# io1986BE1T register map
Registers are 32-bit, access not given, no defined reset value unless marked. A register's access mark holds for its fields unless they carry their own. Addresses are absolute; registers are grouped by the start of their names; [hi:lo] are bit positions; {n}, {i} and the like mark numbered series; 'fields as' and 'values as' point back to an identical list.

## SSP2
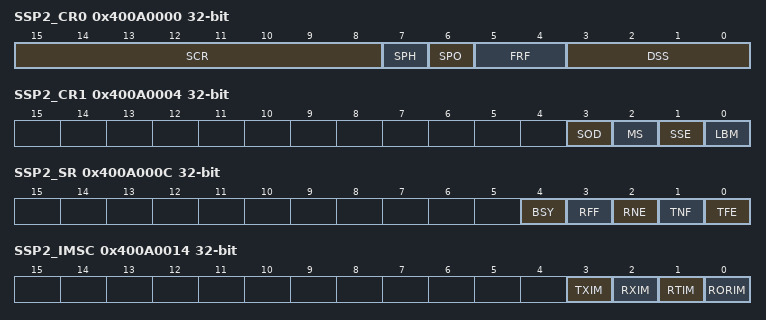
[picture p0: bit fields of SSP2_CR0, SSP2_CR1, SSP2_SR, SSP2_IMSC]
0x400A0000 SSP2_CR0
  [15:8] SCR, [7] SPH, [6] SPO, [5:4] FRF, [3:0] DSS
0x400A0004 SSP2_CR1
  [3] SOD, [2] MS, [1] SSE, [0] LBM
0x400A0008 SSP2_DR
  [15:0] DATA
0x400A000C SSP2_SR
  [4] BSY, [3] RFF, [2] RNE, [1] TNF, [0] TFE
0x400A0010 SSP2_CPSR
  [7:0] CPSDVSR
0x400A0014 SSP2_IMSC
  [3] TXIM, [2] RXIM, [1] RTIM, [0] RORIM
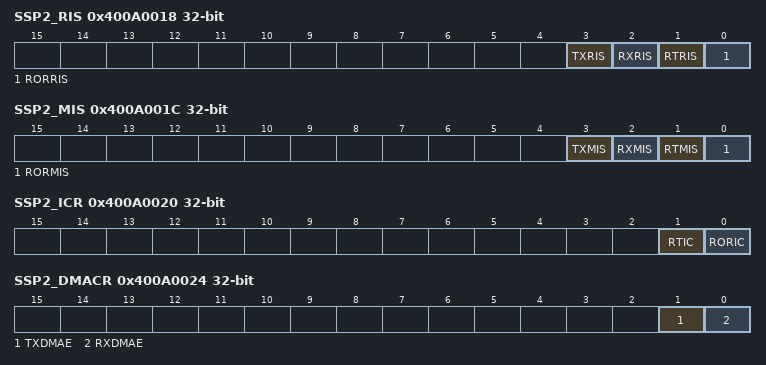
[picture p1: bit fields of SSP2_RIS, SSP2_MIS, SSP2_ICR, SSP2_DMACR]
0x400A0018 SSP2_RIS
  [3] TXRIS, [2] RXRIS, [1] RTRIS, [0] RORRIS
0x400A001C SSP2_MIS
  [3] TXMIS, [2] RXMIS, [1] RTMIS, [0] RORMIS
0x400A0020 SSP2_ICR
  [1] RTIC, [0] RORIC
0x400A0024 SSP2_DMACR
  [1] TXDMAE, [0] RXDMAE

## MIL
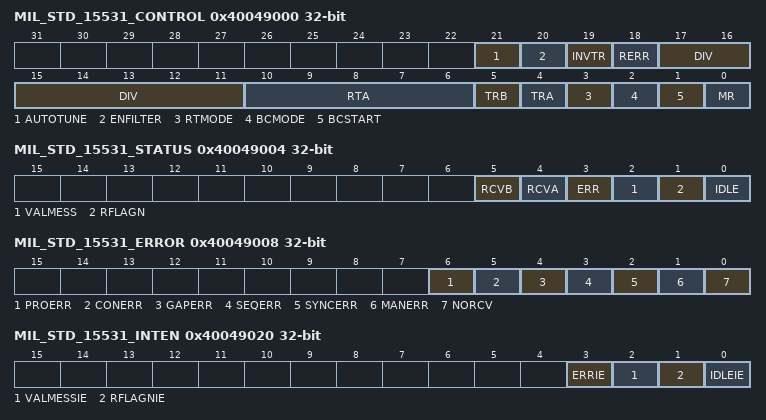
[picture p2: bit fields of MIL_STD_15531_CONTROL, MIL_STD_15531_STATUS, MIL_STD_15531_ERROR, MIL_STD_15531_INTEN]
0x40049000 MIL_STD_15531_CONTROL
  [21] AUTOTUNE, [20] ENFILTER, [19] INVTR, [18] RERR, [17:11] DIV, [10:6] RTA, [5] TRB, [4] TRA, [3] RTMODE, [2] BCMODE, [1] BCSTART, [0] MR
0x40049004 MIL_STD_15531_STATUS
  [5] RCVB, [4] RCVA, [3] ERR, [2] VALMESS, [1] RFLAGN, [0] IDLE
0x40049008 MIL_STD_15531_ERROR
  [6] PROERR, [5] CONERR, [4] GAPERR, [3] SEQERR, [2] SYNCERR, [1] MANERR, [0] NORCV
0x4004900C MIL_STD_15531_CommandWord1
0x40049010 MIL_STD_15531_CommandWord2
0x40049014 MIL_STD_15531_ModeData
0x40049018 MIL_STD_15531_StatusWord1
0x4004901C MIL_STD_15531_StatusWord2
0x40049020 MIL_STD_15531_INTEN
  [3] ERRIE, [2] VALMESSIE, [1] RFLAGNIE, [0] IDLEIE
0x40049024 MIL_STD_15531_MSG
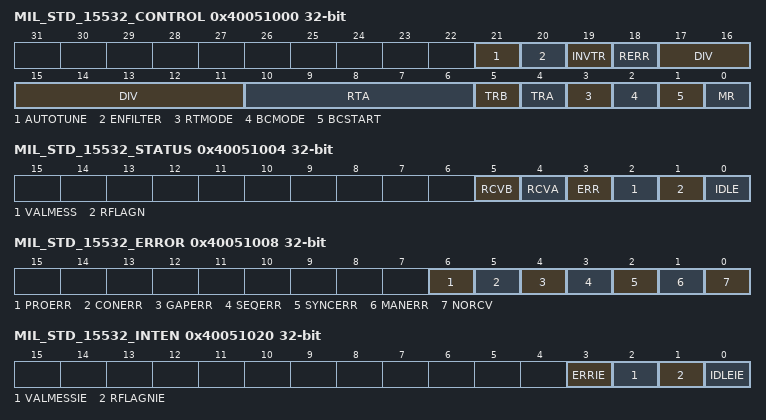
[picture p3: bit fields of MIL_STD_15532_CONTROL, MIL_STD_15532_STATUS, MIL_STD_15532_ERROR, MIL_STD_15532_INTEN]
0x40051000 MIL_STD_15532_CONTROL
  fields as MIL_STD_15531_CONTROL
0x40051004 MIL_STD_15532_STATUS
  [5] RCVB, [4] RCVA, [3] ERR, [2] VALMESS, [1] RFLAGN, [0] IDLE
0x40051008 MIL_STD_15532_ERROR
  fields as MIL_STD_15531_ERROR
0x4005100C MIL_STD_15532_CommandWord1
0x40051010 MIL_STD_15532_CommandWord2
0x40051014 MIL_STD_15532_ModeData
0x40051018 MIL_STD_15532_StatusWord1
0x4005101C MIL_STD_15532_StatusWord2
0x40051020 MIL_STD_15532_INTEN
  [3] ERRIE, [2] VALMESSIE, [1] RFLAGNIE, [0] IDLEIE
0x40051024 MIL_STD_15532_MSG

## ARINC429T
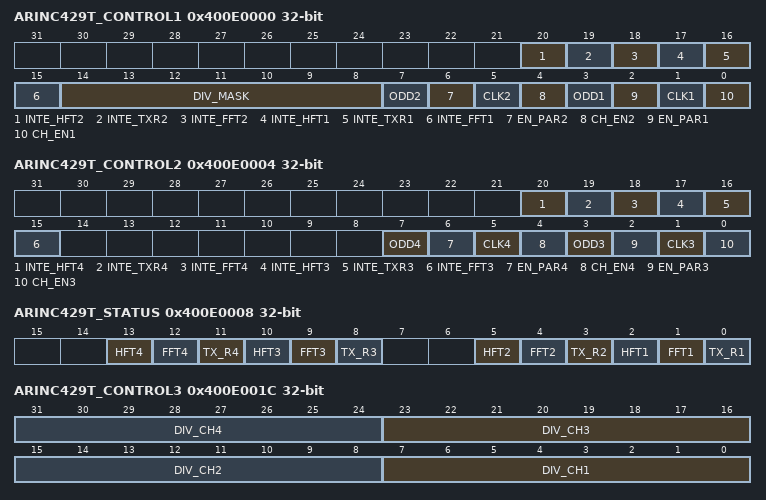
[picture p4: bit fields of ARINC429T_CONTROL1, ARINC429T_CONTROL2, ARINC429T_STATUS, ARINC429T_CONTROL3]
0x400E0000 ARINC429T_CONTROL1
  [20] INTE_HFT2, [19] INTE_TXR2, [18] INTE_FFT2, [17] INTE_HFT1, [16] INTE_TXR1, [15] INTE_FFT1, [14:8] DIV_MASK, [7] ODD2, [6] EN_PAR2, [5] CLK2, [4] CH_EN2, [3] ODD1, [2] EN_PAR1, [1] CLK1, [0] CH_EN1
0x400E0004 ARINC429T_CONTROL2
  [20] INTE_HFT4, [19] INTE_TXR4, [18] INTE_FFT4, [17] INTE_HFT3, [16] INTE_TXR3, [15] INTE_FFT3, [7] ODD4, [6] EN_PAR4, [5] CLK4, [4] CH_EN4, [3] ODD3, [2] EN_PAR3, [1] CLK3, [0] CH_EN3
0x400E0008 ARINC429T_STATUS
  [13] HFT4, [12] FFT4, [11] TX_R4, [10] HFT3, [9] FFT3, [8] TX_R3, [5] HFT2, [4] FFT2, [3] TX_R2, [2] HFT1, [1] FFT1, [0] TX_R1
{0x400E0008+4i} ARINC429T_DATA{i}_T (i=1..4)
0x400E001C ARINC429T_CONTROL3
  [8n-1:8n-8] DIV_CH{n} (n=1..4)

## ARINC429R
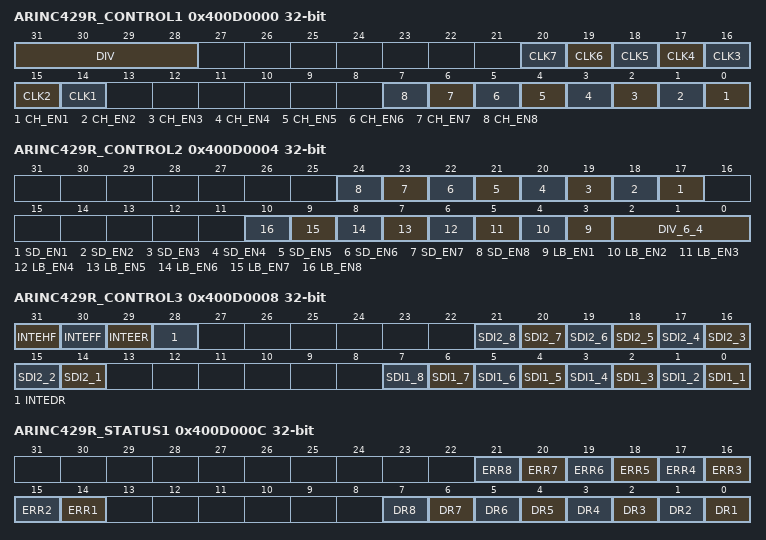
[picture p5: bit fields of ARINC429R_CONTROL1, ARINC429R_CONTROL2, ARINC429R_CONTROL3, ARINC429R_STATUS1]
0x400D0000 ARINC429R_CONTROL1
  [31:28] DIV, [n+13] CLK{n} (n=1..7), [n-1] CH_EN{n} (n=1..8)
0x400D0004 ARINC429R_CONTROL2
  [n+16] SD_EN{n} (n=1..8), [n+2] LB_EN{n} (n=1..8), [2:0] DIV_6_4
0x400D0008 ARINC429R_CONTROL3
  [31] INTEHF, [30] INTEFF, [29] INTEER, [28] INTEDR, [n+13] SDI2_{n} (n=1..8), [n-1] SDI1_{n} (n=1..8)
0x400D000C ARINC429R_STATUS1
  [n+13] ERR{n} (n=1..8), [n-1] DR{n} (n=1..8)
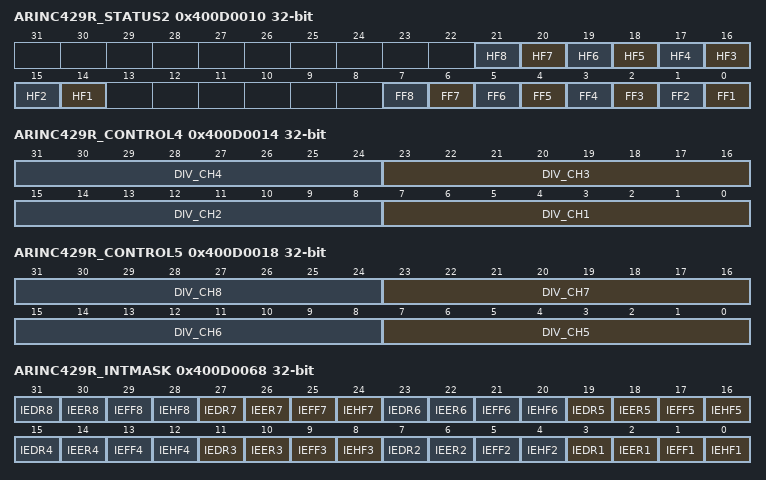
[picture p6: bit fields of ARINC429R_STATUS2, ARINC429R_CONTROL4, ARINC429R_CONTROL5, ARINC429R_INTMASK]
0x400D0010 ARINC429R_STATUS2
  [n+13] HF{n} (n=1..8), [n-1] FF{n} (n=1..8)
0x400D0014 ARINC429R_CONTROL4
  [8n-1:8n-8] DIV_CH{n} (n=1..4)
0x400D0018 ARINC429R_CONTROL5
  [8n-33:8n-40] DIV_CH{n} (n=5..8)
0x400D001C ARINC429R_CHANNEL
0x400D0020 ARINC429R_LABEL
0x400D0024 ARINC429R_DATA_R
0x400D0068 ARINC429R_INTMASK
  [4n-1] IEDR{n} (n=1..8), [4n-2] IEER{n} (n=1..8), [4n-3] IEFF{n} (n=1..8), [4n-4] IEHF{n} (n=1..8)
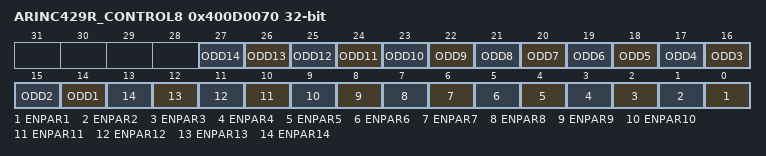
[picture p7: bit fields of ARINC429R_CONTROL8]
0x400D0070 ARINC429R_CONTROL8
  [n+13] ODD{n} (n=1..14), [n-1] ENPAR{n} (n=1..14)

## PHY
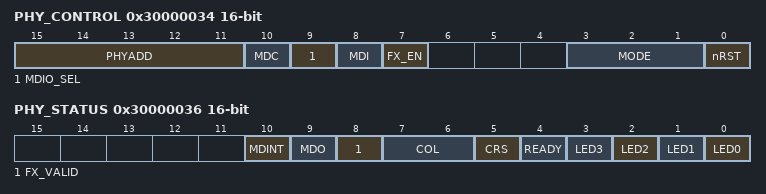
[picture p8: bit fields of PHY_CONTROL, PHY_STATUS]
0x30000034 PHY_CONTROL 16-bit
  [15:11] PHYADD, [10] MDC, [9] MDIO_SEL, [8] MDI, [7] FX_EN, [3:1] MODE, [0] nRST
0x30000036 PHY_STATUS 16-bit
  [10] MDINT, [9] MDO, [8] FX_VALID, [7:6] COL, [5] CRS, [4] READY, [n] LED{n} (n=0..3)

## SFR
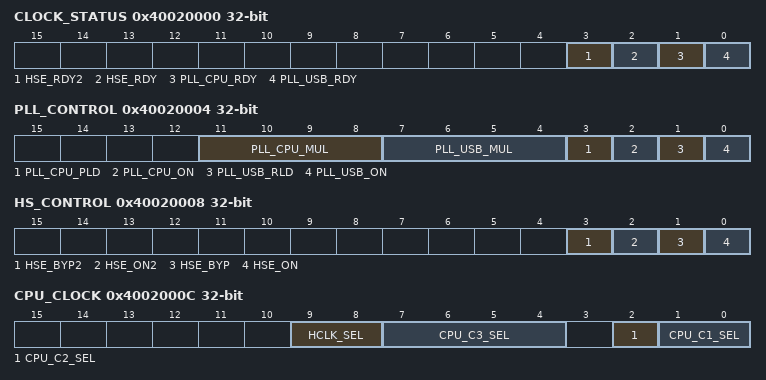
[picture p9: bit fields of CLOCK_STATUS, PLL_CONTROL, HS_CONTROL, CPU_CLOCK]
0x40020000 CLOCK_STATUS
  [3] HSE_RDY2, [2] HSE_RDY, [1] PLL_CPU_RDY, [0] PLL_USB_RDY
0x40020004 PLL_CONTROL
  [11:8] PLL_CPU_MUL, [7:4] PLL_USB_MUL, [3] PLL_CPU_PLD, [2] PLL_CPU_ON, [1] PLL_USB_RLD, [0] PLL_USB_ON
0x40020008 HS_CONTROL
  [3] HSE_BYP2, [2] HSE_ON2, [1] HSE_BYP, [0] HSE_ON
0x4002000C CPU_CLOCK
  [9:8] HCLK_SEL, [7:4] CPU_C3_SEL, [2] CPU_C2_SEL, [1:0] CPU_C1_SEL
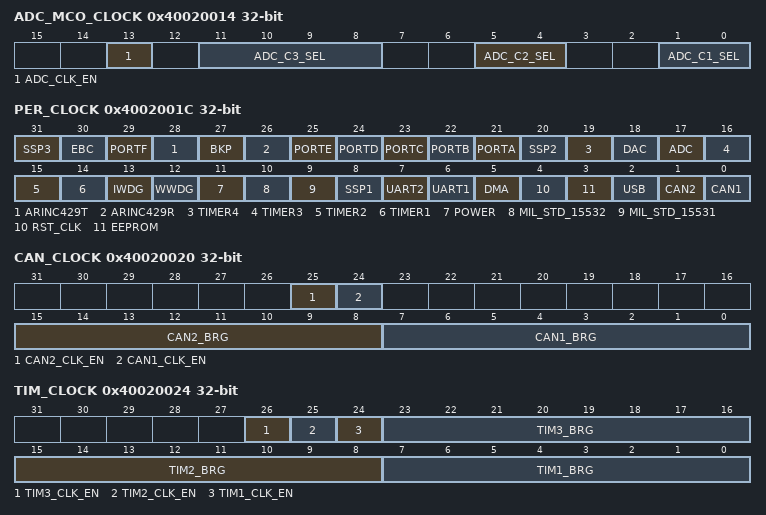
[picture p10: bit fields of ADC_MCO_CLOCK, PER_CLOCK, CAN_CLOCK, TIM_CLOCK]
0x40020014 ADC_MCO_CLOCK
  [13] ADC_CLK_EN, [11:8] ADC_C3_SEL, [5:4] ADC_C2_SEL, [1:0] ADC_C1_SEL
0x4002001C PER_CLOCK
  [31] SSP3, [30] EBC, [29] PORTF, [28] ARINC429T, [27] BKP, [26] ARINC429R, [25] PORTE, [24] PORTD, [23] PORTC, [22] PORTB, [21] PORTA, [20] SSP2, [19] TIMER4, [18] DAC, [17] ADC, [16] TIMER3, [15] TIMER2, [14] TIMER1, [13] IWDG, [12] WWDG, [11] POWER, [10] MIL_STD_15532, [9] MIL_STD_15531, [8] SSP1, [7] UART2, [6] UART1, [5] DMA, [4] RST_CLK, [3] EEPROM, [2] USB, [1] CAN2, [0] CAN1
0x40020020 CAN_CLOCK
  [25] CAN2_CLK_EN, [24] CAN1_CLK_EN, [15:8] CAN2_BRG, [7:0] CAN1_BRG
0x40020024 TIM_CLOCK
  [26] TIM3_CLK_EN, [25] TIM2_CLK_EN, [24] TIM1_CLK_EN, [23:16] TIM3_BRG, [15:8] TIM2_BRG, [7:0] TIM1_BRG
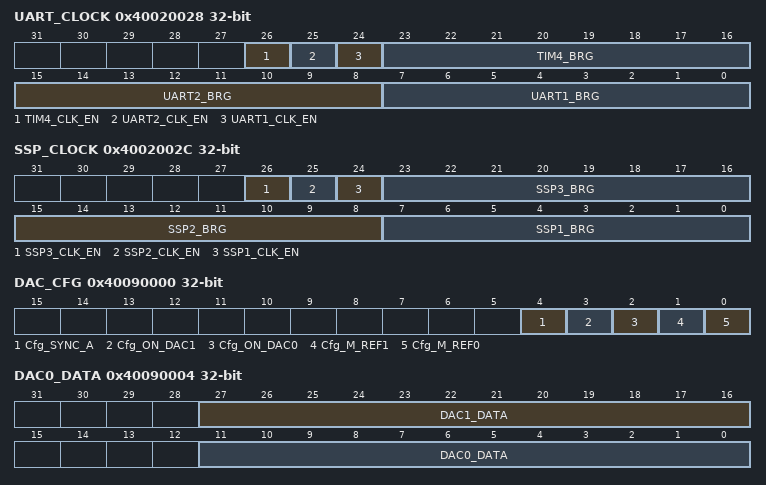
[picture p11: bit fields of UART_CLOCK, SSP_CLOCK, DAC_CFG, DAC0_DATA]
0x40020028 UART_CLOCK
  [26] TIM4_CLK_EN, [25] UART2_CLK_EN, [24] UART1_CLK_EN, [23:16] TIM4_BRG, [15:8] UART2_BRG, [7:0] UART1_BRG
0x4002002C SSP_CLOCK
  [26] SSP3_CLK_EN, [25] SSP2_CLK_EN, [24] SSP1_CLK_EN, [23:16] SSP3_BRG, [15:8] SSP2_BRG, [7:0] SSP1_BRG
0x40028008 CTRL_BASE_PTR
  [31:10] CTRL_BASE_PTR
0x4002800C ALT_CTRL_BASE_PTR
0x4002804C ERR_CLR
  [0] ERR_CLR
0x40088004 ADC2_CFG
  [17] ADC1_OP
0x40090000 DAC_CFG
  [4] Cfg_SYNC_A, [3] Cfg_ON_DAC1, [2] Cfg_ON_DAC0, [1] Cfg_M_REF1, [0] Cfg_M_REF0
0x40090004 DAC0_DATA
  [27:16] DAC1_DATA, [11:0] DAC0_DATA
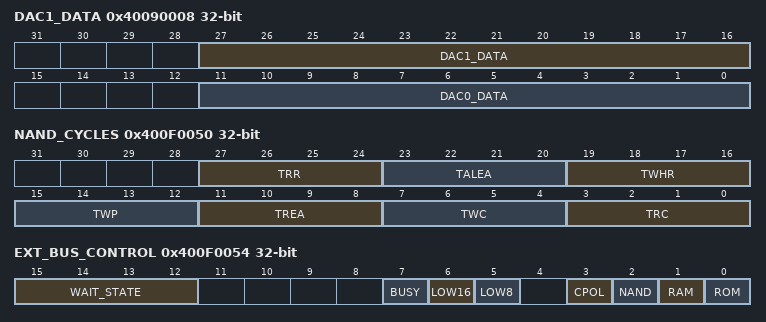
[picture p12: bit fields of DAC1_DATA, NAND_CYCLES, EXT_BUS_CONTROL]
0x40090008 DAC1_DATA
  [27:16] DAC1_DATA, [11:0] DAC0_DATA
0x400F0050 NAND_CYCLES
  [27:24] TRR, [23:20] TALEA, [19:16] TWHR, [15:12] TWP, [11:8] TREA, [7:4] TWC, [3:0] TRC
0x400F0054 EXT_BUS_CONTROL
  [15:12] WAIT_STATE, [7] BUSY, [6] LOW16, [5] LOW8, [3] CPOL, [2] NAND, [1] RAM, [0] ROM
